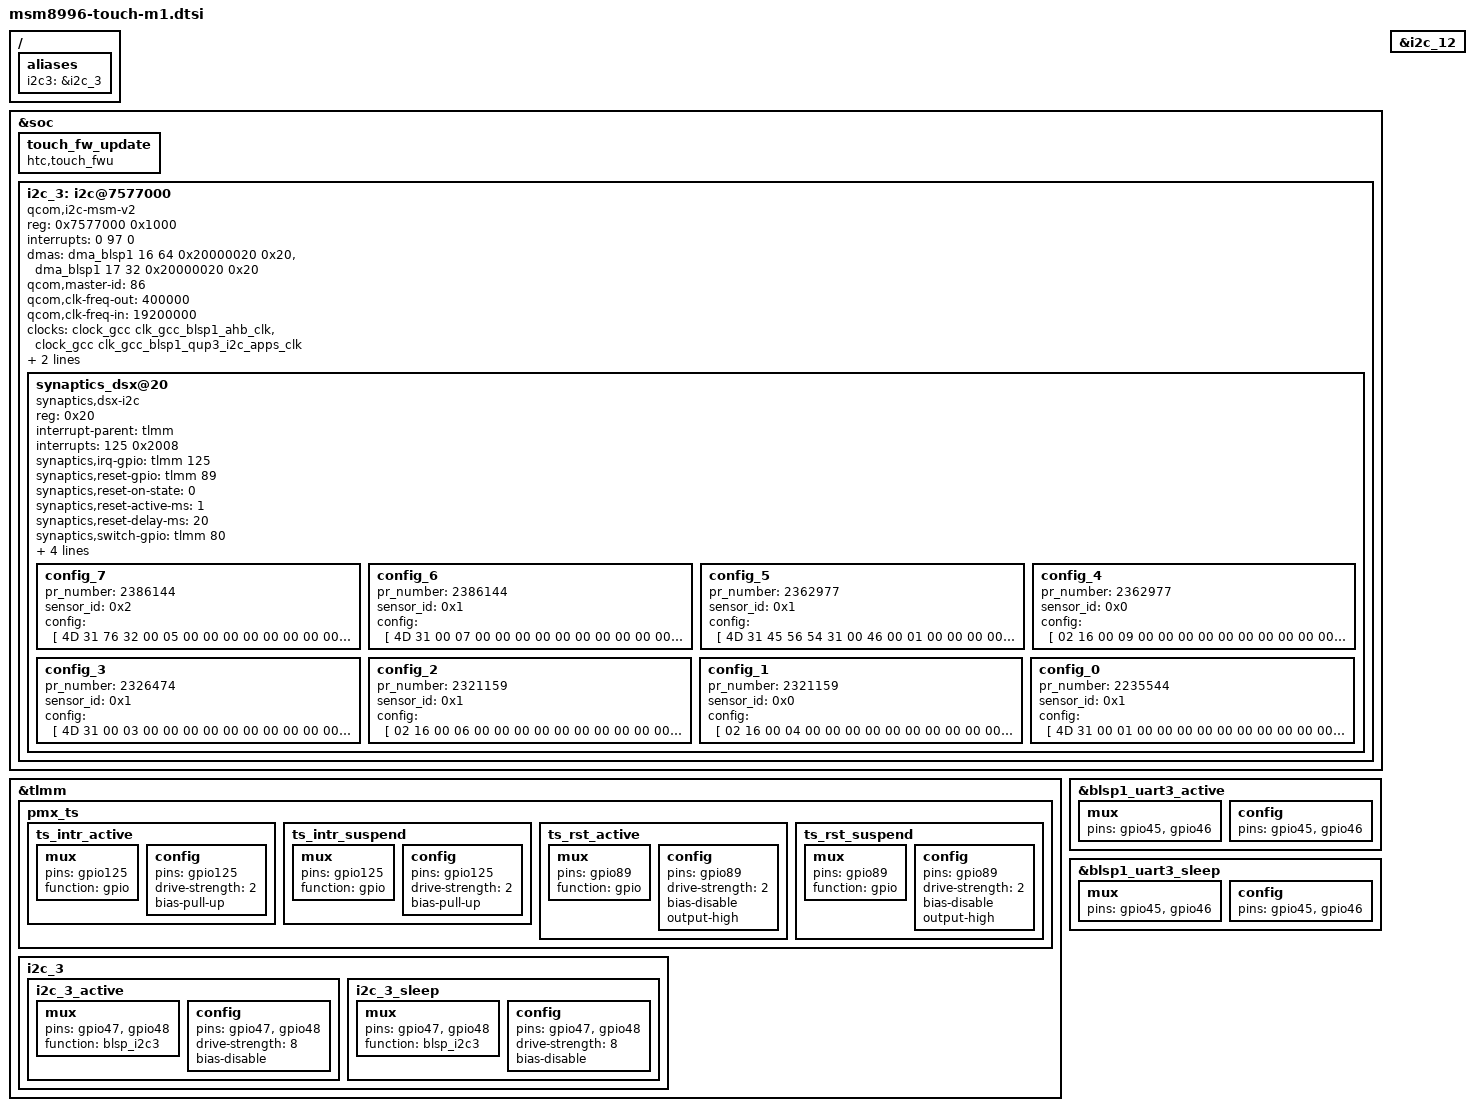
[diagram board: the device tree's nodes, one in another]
&soc {
	touch_fw_update {
		compatible = "htc,touch_fwu";
	};
};

&tlmm {
	pmx_ts {
		ts_intr_active:ts_intr_active {
			mux {
				pins = "gpio125";
				function = "gpio";
			};

			config {
				pins = "gpio125";
				drive-strength = <2>;
				bias-pull-up;
			};
		};
		ts_intr_suspend:ts_intr_suspend {
			mux {
				pins = "gpio125";
				function = "gpio";
			};

			config {
				pins = "gpio125";
				drive-strength = <2>;
				bias-pull-up;
			};
		};

		ts_rst_active:ts_rst_active {
			mux {
				pins = "gpio89";
				function = "gpio";
			};

			config {
				pins = "gpio89";
				drive-strength = <2>;
				bias-disable; /* No PULL */
				output-high;
			};
		};
		ts_rst_suspend:ts_rst_suspend {
			mux {
				pins = "gpio89";
				function = "gpio";
			};

			config {
				pins = "gpio89";
				drive-strength = <2>;
				bias-disable;
				output-high;
			};
		};
	};

	i2c_3 {
		i2c_3_active: i2c_3_active {
			mux {
				pins = "gpio47", "gpio48";
				function = "blsp_i2c3";
			};

			config {
				pins = "gpio47", "gpio48";
				drive-strength = <8>;
				bias-disable;
			};
		};

		i2c_3_sleep: i2c_3_sleep {
			mux {
				pins = "gpio47", "gpio48";
				function = "blsp_i2c3";
			};

			config {
				pins = "gpio47", "gpio48";
				drive-strength = <8>;
				bias-disable;
			};
		};
	};
};

&blsp1_uart3_active {
	mux {
		pins = "gpio45", "gpio46";
	};

	config {
		pins = "gpio45", "gpio46";
	};
};

&blsp1_uart3_sleep {
	mux {
		pins = "gpio45", "gpio46";
	};

	config {
		pins = "gpio45", "gpio46";
	};
};

/ {
	aliases {
		i2c3 = &i2c_3;
	};
};

&soc {
	i2c_3: i2c@7577000 { /* BLSP1 QUP3 */
		compatible = "qcom,i2c-msm-v2";
		#address-cells = <1>;
		#size-cells = <0>;
		reg = <0x7577000  0x1000>;
		reg-names = "qup_phys_addr";
		interrupt-names = "qup_irq";
		interrupts = <0 97 0>;
		dmas = <&dma_blsp1 16 64 0x20000020 0x20>,
			<&dma_blsp1 17 32 0x20000020 0x20>;
		dma-names = "tx", "rx";
		qcom,master-id = <86>;
		qcom,clk-freq-out = <400000>;
		qcom,clk-freq-in  = <19200000>;
		clock-names = "iface_clk", "core_clk";
		clocks = <&clock_gcc clk_gcc_blsp1_ahb_clk>,
			 <&clock_gcc clk_gcc_blsp1_qup3_i2c_apps_clk>;
		pinctrl-names = "i2c_active", "i2c_sleep";
		pinctrl-0 = <&i2c_3_active>;
		pinctrl-1 = <&i2c_3_sleep>;
	};
};

&i2c_12 {
	/delete-node/ synaptics@20;
};

&i2c_3 {
	synaptics_dsx@20 {
		compatible = "synaptics,dsx-i2c";
		reg = <0x20>;
		interrupt-parent = <&tlmm>;
		interrupts = <125 0x2008>;
		synaptics,irq-gpio = <&tlmm 125 0x2008>;  /* IRQF_ONESHOT | IRQF_TRIGGER_LOW */
		synaptics,reset-gpio = <&tlmm 89 0x00>;
		synaptics,reset-on-state = <0>;
		synaptics,reset-active-ms = <1>;
		synaptics,reset-delay-ms = <20>;
		synaptics,switch-gpio = <&tlmm 80 0x00>;
		synaptics,update-feature = <3>;
		synaptics,tw-pin-mask = <0x3>;
		pinctrl-names = "pmx_ts_active", "pmx_ts_suspend";
		pinctrl-0 = <&ts_rst_active &ts_intr_active>;
		pinctrl-1 = <&ts_rst_suspend &ts_intr_suspend>;

		config_7 { /* S3708, EVT2 w/o Force */
			pr_number     = <2386144>;
			sensor_id = <0x2>;
			config = [
				4D 31 76 32 00 05 00 00
				00 00 00 00 00 00 00 00
				00 00 00 00 00 00 00 00
				00 00 00 00 00 00 00 00
				00 07 01 14 05 51 0E 9F
				05 FF 09 39 40 9E 40 00
				00 20 20 11 1E 1E 05 F1
				10 9F 02 2D 1C 00 1B 00
				DC CC 55 CC 25 0D 05 8C
				00 00 10 12 78 0F 0A 78
				00 01 01 07 04 04 32 28
				08 7D 26 26 80 80 00 00
				C8 01 64 00 05 0A 00 FF
				05 01 28 FF C0 53 5B 80
				4A 26 00 40 50 32 50 00
				00 00 00 9F 05 FF 09 3C
				32 00 00 00 00 9F 05 FF
				09 1E 05 1E 04 0A 04 0A
				00 0A 04 04 00 0A 78 02
				00 7D 00 02 00 C8 00 00
				00 96 00 00 00 00 01 05
				0A 00 00 00 78 00 96 00
				32 00 00 00 00 00 00 00
				00 00 0D 00 00 14 03 0C
				0F 0A 00 4B 00 00 FF FF
				FF FF FF FF FF FF FF FF
				FF FF FF FF FF FF FF FF
				FF FF FF FF FF FF FF FF
				FF FF FF FF FF FF FF 00
				01 00 00 32 00 14 00 14
				00 64 00 64 00 10 00 10
				00 7D 00 7D 00 40 66 58
				1B 28 00 FF FF FF FF FF
				FF FF FF FF FF FF FF FF
				FF FF FF 01 00 00 00 00
				00 00 00 00 00 00 00 00
				00 00 00 00 00 00 00 00
				00 00 FF 00 FF 14 55 09
				0E 3C 0A 0F 64 64 00 00
				00 00 00 00 00 00 00 00
				00 00 00 00 00 00 00 00
				FF FF FF FF FF FF FF FF
				FF FF FF FF FF FF FF FF
				FF FF FF FF FF FF FF FF
				FF FF FF FF FF FF FF FF
				FF FF FF FF FF FF FF FF
				FF FF FF FF FF FF FF FF
				FF FF FF FF FF FF FF FF
				FF FF FF FF FF FF FF FF
				00 00 A0 00 80 04 1B 00
				00 FF E8 03 FF FF CC 03
				98 3A 00 C0 80 04 10 0A
				18 00 79 08 05 00 01 2C
				01 03 00 03 03 07 07 03
				2C 01 01 04 03 2F 00 15
				00 00 00 05 00 02 27 83
				2E 00 15 00 01 00 05 00
				02 28 83 2D 00 14 00 02
				00 05 00 02 29 03 2C 00
				14 00 03 00 05 00 02 29
				83 2B 00 13 00 05 00 03
				00 01 24 03 29 00 13 00
				07 00 03 00 01 25 83 28
				00 12 00 09 00 03 00 01
				27 82 26 00 11 00 0B 00
				03 00 01 28 03 03 03 03
				03 03 03 03 03 03 03 03
				03 03 03 03 03 00 00 00
				00 00 00 00 00 00 00 00
				00 00 00 00 00 00 23 00
				06 00 50 00 0A 32 00 01
				1B 01 06 46 00 28 00 28
				00 64 00 1E 03 0C 0C 14
				28 04 00 00 00 00 00 00
				00 00 00 00 14 00 80 07
				01 07 07 1D 1D 00 00 07
				07 01 07 07 1D 1D 00 00
				07 04 04 50 00 07 03 00
				2F 22 00 05 0B 00 22 02
				00 00 00 0D BB BB AA 0D
				66 66 00 0D 00 00 AA 0D
				EE EE 00 01 00 DA 00 13
				00 04 00 71 76 74 7A 7C
				7D 7A 7B 7D 7D 80 7F 7D
				7C 76 7A 76 80 80 80 80
				80 80 80 80 80 80 80 80
				80 80 80 80 80 78 7C 80
				7C 7A 7D 7B 7F 7C 7A 7A
				7B 7A 78 76 73 71 71 6E
				69 69 68 69 66 5D 5D 5F
				57 53 4E 80 80 80 80 00
				00 00 FF FF FF FF FF FF
				FF FF 51 51 51 51 CD 0D
				04 83 10 10 10 10 61 24
				64 01 17 16 12 11 0F 10
				0B 0A 05 04 18 1A 0D 13
				0E 08 09 FF FF FF FF FF
				FF FF FF FF FF FF FF FF
				FF FF FF FF 30 2E 2F 28
				29 2A 2C 2B 26 25 23 24
				22 35 39 36 37 33 32 2D
				27 34 38 31 3A 3B 3E 3D
				3C 3F FF FF FF FF 00 10
				00 10 00 10 00 10 80 80
				80 80 80 80 80 80 80 80
				80 80 80 80 80 80 80 80
				80 80 80 80 80 80 80 80
				80 80 80 80 80 80 80 80
				C0 B3 A6 9A 8D 80 80 80
				80 80 80 80 80 80 80 80
				80 80 80 80 80 80 80 80
				80 80 80 80 80 80 80 80
				80 80 00 18 00 18 00 10
				00 10 00 00 1C 1D 1E 1F
				FF FF FF FF 00 00 0F 00
				44 44 A0
			];
		};

		config_6 { /* S3708, EVT1 w/o Force */
			pr_number     = <2386144>;
			sensor_id = <0x1>;
			config = [
				4D 31 00 07 00 00 00 00
				00 00 00 00 00 00 00 00
				00 00 00 00 00 00 00 00
				00 00 00 00 00 00 00 00
				00 0F 01 14 05 51 0E 9F
				05 FF 09 39 40 9E 40 00
				00 20 00 11 1E 1E 05 CA
				10 19 02 2D 19 01 18 01
				80 D2 DF D0 25 0D 05 8C
				00 00 0E 10 50 0F 0A 78
				00 01 01 07 04 04 32 28
				08 7D 26 26 80 80 00 00
				C8 01 64 00 05 28 00 FF
				05 01 28 FF C0 53 5B 80
				5A 1A 00 40 50 3C 50 00
				00 00 00 4C 04 6C 07 3C
				32 00 00 00 00 4C 04 6C
				07 1E 05 1E 04 0A 04 0A
				00 0A 04 04 00 0A 78 02
				00 7D 00 02 00 C8 00 00
				00 96 00 00 00 00 01 05
				0A 00 00 00 78 00 96 00
				32 00 00 00 00 00 00 00
				00 00 0D 00 00 14 03 0C
				0F 0A 00 4B 00 00 FF FF
				FF FF FF FF FF FF FF FF
				FF FF FF FF FF FF FF FF
				FF FF FF FF FF FF FF FF
				FF FF FF FF FF FF FF 00
				01 00 00 32 00 14 00 14
				00 64 00 64 00 10 00 10
				00 7D 00 7D 00 40 66 58
				1B 28 00 FF FF FF FF FF
				FF FF FF FF FF FF FF FF
				FF FF FF 01 00 00 00 00
				00 00 00 00 00 00 00 00
				00 00 00 00 00 00 00 00
				00 00 FF 00 FF 14 55 09
				0E 3C 0A 0F 64 64 00 00
				00 00 00 00 00 00 00 00
				00 00 00 00 00 00 00 00
				FF FF FF FF FF FF FF FF
				FF FF FF FF FF FF FF FF
				FF FF FF FF FF FF FF FF
				FF FF FF FF FF FF FF FF
				FF FF FF FF FF FF FF FF
				FF FF FF FF FF FF FF FF
				FF FF FF FF FF FF FF FF
				FF FF FF FF FF FF FF FF
				00 00 64 00 80 04 1B 00
				00 FF 40 1F FF FF CC 03
				98 3A 00 C0 80 04 10 0A
				18 00 79 08 08 00 01 10
				27 06 00 02 02 07 07 05
				10 27 01 04 03 2F 00 15
				00 00 00 05 00 02 27 83
				2E 00 15 00 01 00 05 00
				02 28 83 2D 00 14 00 02
				00 05 00 02 29 03 2C 00
				14 00 03 00 05 00 02 29
				83 2B 00 13 00 05 00 03
				00 01 24 03 29 00 13 00
				07 00 03 00 01 25 83 28
				00 12 00 09 00 03 00 01
				27 82 26 00 11 00 0B 00
				03 00 01 28 03 03 03 03
				03 03 03 03 03 03 03 03
				03 03 03 03 03 00 00 00
				00 00 00 00 00 00 00 00
				00 00 00 00 00 00 23 00
				06 00 50 00 0A 19 00 01
				1B 01 06 46 00 28 00 28
				00 64 00 1E 03 0C 0C 14
				28 04 00 00 00 00 00 00
				00 00 00 00 14 00 80 07
				01 07 07 1D 1D 00 00 07
				07 01 07 07 1D 1D 00 00
				07 04 04 50 00 07 03 00
				2F 22 00 05 0B 00 22 02
				00 00 00 0D BB BB AA 0D
				66 66 00 0D 00 00 00 0D
				EE EE AA 01 00 DA 00 13
				00 04 00 71 76 74 7A 7C
				7D 7A 7B 7D 7D 80 7F 7D
				7C 76 7A 76 80 80 80 80
				80 80 80 80 80 80 80 80
				80 80 80 80 80 78 7C 80
				7C 7A 7D 7B 7F 7C 7A 7A
				7B 7A 78 76 73 71 71 6E
				69 69 68 69 66 5D 5D 5F
				57 53 4E 80 80 80 80 00
				00 00 FF FF FF FF FF FF
				FF FF 51 51 51 51 CD 0D
				04 83 10 10 10 10 61 24
				64 01 36 12 35 13 39 1A
				38 31 32 3A 37 14 34 15
				33 17 11 FF FF FF FF FF
				FF FF FF FF FF FF FF FF
				FF FF FF FF 2E 2D 30 28
				2F 2A 29 2C 27 2B 1B 1D
				1E 1F 1C 0D 10 0F 0C 07
				0E 08 09 03 06 02 0A 0B
				04 05 FF FF FF FF 00 10
				00 10 00 10 00 10 80 80
				80 80 80 80 80 80 80 80
				80 80 80 80 80 80 80 80
				80 80 80 80 80 80 80 80
				80 80 80 80 80 80 80 80
				C0 B3 A6 9A 8D 80 80 80
				80 80 80 80 80 80 80 80
				80 80 80 80 80 80 80 80
				80 80 80 80 80 80 80 80
				80 80 00 18 00 18 00 10
				00 10 00 00 16 19 18 24
				FF FF FF FF 0B 0B 04 00
				44 44 FA
			];
		};

		config_5 { /* S3718, EVT1 w/ Force */
			pr_number     = <2362977>;
			sensor_id = <0x1>;
			config = [
				4D 31 45 56 54 31 00 46
				00 01 00 00 00 00 00 00
				00 00 00 00 00 00 00 00
				00 00 00 00 00 00 00 00
				00 47 03 1E 05 51 0E A0
				05 00 0A 39 40 9E 40 00
				00 00 00 11 1E 01 1E 05
				DB 13 D6 04 2D 1B 02 1B
				02 1B D7 02 D5 25 0D 05
				8C 00 02 40 0C 13 80 0F
				0A 20 1A 01 01 26 26 80
				80 00 00 03 80 03 0C 06
				00 20 0F 01 28 00 C0 53
				5B 80 5C 25 01 40 40 32
				00 00 00 00 00 00 00 00
				00 00 00 CD 0A 00 09 00
				00 FF FF FF FF FF FF FF
				FF FF FF FF FF FF FF FF
				FF FF FF FF FF FF FF FF
				FF FF FF FF FF FF FF FF
				FF FF 00 01 00 00 8C 00
				00 00 00 00 2C 01 2C 01
				10 00 10 00 C8 00 C8 00
				66 66 88 13 00 00 FF FF
				FF FF FF FF FF FF FF FF
				FF FF FF FF FF FF 00 6C
				00 CC 03 C0 00 C0 06 36
				00 02 04 60 00 20 07 09
				09 00 00 00 00 FF 00 FF
				FF 55 09 0E 3C 0A 0A 64
				64 FF FF FF FF FF FF FF
				FF FF FF FF FF FF FF FF
				FF FF FF FF FF FF FF FF
				FF FF FF FF FF FF FF FF
				FF FF FF FF FF FF FF FF
				FF FF FF FF FF FF FF FF
				FF FF FF FF FF FF FF FF
				FF FF FF FF FF FF FF FF
				FF 17 05 05 00 0F 00 BC
				02 1E 00 05 00 0F 00 BC
				02 1E 00 0A 19 01 0C 00
				02 01 0C 00 02 AF 01 01
				01 01 01 00 00 00 00 00
				32 00 0A 00 96 00 0A 00
				09 00 FF FF FF FF FF FF
				FF FF FF FF FF FF FF FF
				FF 21 3B 00 26 01 20 3F
				3C 25 3D 22 23 3E FF FF
				07 01 07 07 1D 1D 00 00
				07 00 07 01 07 07 1D 1D
				00 00 07 00 04 04 50 00
				07 03 00 35 22 00 05 0B
				00 22 02 00 0D 88 88 00
				0D BB BB 8A 4C 1D A0 0E
				A0 00 00 73 00 80 04 1B
				00 00 FF 7C 8C FF FF FF
				FF FF FF 00 C0 80 04 10
				0A 18 00 79 0C FF FF 01
				FF FF FF FF 00 FF FF FF
				FF 02 02 07 07 05 46 A5
				01 04 03 2F 00 15 00 00
				00 05 00 02 27 03 2D 00
				14 00 02 00 05 00 02 29
				83 2B 00 14 00 04 00 05
				00 02 2A 83 2A 00 13 00
				06 00 03 00 01 25 03 28
				00 12 00 09 00 03 00 01
				27 02 26 00 11 00 0C 00
				03 00 01 28 82 24 00 10
				00 0F 00 07 00 02 25 82
				22 00 10 00 12 00 07 00
				02 26 03 03 03 03 03 03
				03 03 03 03 03 03 03 03
				03 03 03 00 00 00 00 00
				00 00 00 00 00 00 00 00
				00 00 00 00 23 00 06 00
				A6 00 14 64 02 01 1B 00
				00 08 08 A0 00 A0 00 50
				50 00 00 00 00 00 00 00
				00 14 80 07 01 07 07 1D
				1D 00 00 07 07 01 07 07
				1D 1D 00 00 07 04 04 50
				00 07 03 00 2F 22 00 05
				0B 00 22 02 00 00 00 0D
				FF FF 55 0D 44 44 00 13
				13 13 13 12 13 13 13 13
				13 13 13 14 14 14 14 17
				04 07 06 05 05 03 05 06
				06 06 04 05 05 00 00 00
				00 18 17 16 16 16 16 16
				15 15 15 15 15 15 15 15
				15 15 15 15 15 15 15 15
				15 15 15 14 14 14 15 00
				00 00 00 01 00 F8 00 45
				00 05 00 76 78 7A 7B 7A
				7D 7D 7F 7D 7F 7D 80 7C
				7D 7B 7A 78 00 00 00 00
				00 00 00 00 00 00 00 00
				00 00 00 00 00 7A 78 7A
				7D 7D 80 7A 77 7A 72 77
				6F 73 72 6E 6C 6A 64 64
				61 57 54 54 51 4A 3F 38
				3A 34 31 00 00 00 00 00
				04 03 05 00 00 00 FF FF
				FF FF FF FF FF FF 51 51
				51 51 CD 0D 04 01 36 12
				35 13 39 1A 38 31 32 3A
				37 14 34 15 33 17 11 FF
				FF FF FF FF FF FF FF FF
				FF FF FF FF FF FF FF FF
				2E 2D 30 28 2F 2A 29 2C
				27 2B 1B 1D 1E 1F 1C 0D
				10 0F 0C 07 0E 08 09 03
				06 02 0A 0B 04 05 FF FF
				FF FF 00 00 16 19 18 24
				FF FF FF FF 0B 0B 04 A1
				00 50 00 00 00 C8 50 05
				09 A0 0E A0 00 00 00 3C
				5C 00 00 00 08 7F 00 04
				02 04 3C 00 00 00 00 00
				00 00 A0 05 00 0A 99 00
			];
		};

		config_4 { /* S3718, prototype P */
			pr_number     = <2362977>;
			sensor_id = <0x0>;
			config = [
				02 16 00 09 00 00 00 00
				00 00 00 00 00 00 00 00
				00 00 00 00 00 00 00 00
				00 00 00 00 00 00 00 00
				00 07 03 1E 05 51 0E A0
				05 00 0A 39 40 9E 40 00
				00 39 00 11 1E 01 1E 05
				DB 13 D6 04 2D 30 00 30
				00 8F D9 E4 D8 25 0D 05
				8C 00 C2 40 0A 0C 80 0F
				0A 50 1A 01 01 26 26 80
				80 00 00 03 80 03 0C 06
				00 20 0F 01 28 00 C0 53
				5B 80 33 0D 00 40 40 32
				00 00 00 00 00 00 00 00
				00 00 00 EF 0A 00 09 00
				00 FF FF FF FF FF FF FF
				FF FF FF FF FF FF FF FF
				FF FF FF FF FF FF FF FF
				FF FF FF FF FF FF FF FF
				FF FF 00 01 00 00 8C 00
				00 00 00 00 2C 01 2C 01
				10 00 10 00 C8 00 C8 00
				66 66 88 13 00 00 FF FF
				FF FF FF FF FF FF FF FF
				FF FF FF FF FF FF 00 6C
				00 CC 03 C0 00 C0 06 36
				00 02 04 60 00 20 07 09
				09 00 00 00 00 FF 00 FF
				FF 55 09 0E 3C 0A 0A 64
				64 FF FF FF FF FF FF FF
				FF FF FF FF FF FF FF FF
				FF FF FF FF FF FF FF FF
				FF FF FF FF FF FF FF FF
				FF FF FF FF FF FF FF FF
				FF FF FF FF FF FF FF FF
				FF FF FF FF FF FF FF FF
				FF FF FF FF FF FF FF FF
				FF 17 05 05 00 0F 00 BC
				02 1E 00 05 00 0F 00 BC
				02 1E 00 0A 19 01 0C 00
				02 01 0C 00 02 AF 01 01
				01 01 01 00 00 00 00 00
				32 00 0A 00 96 00 0A 00
				09 00 FF FF FF FF FF FF
				FF FF FF FF FF FF FF FF
				FF FF FF FF FF FF FF FF
				FF FF FF FF FF FF FF FF
				07 01 07 07 1D 1D 00 00
				07 00 07 01 07 07 1D 1D
				00 00 07 00 04 04 50 00
				07 03 00 35 22 00 05 0B
				00 22 02 00 0D 88 88 00
				0D BB BB 8A 4C 1D A0 0E
				A0 00 00 77 00 80 04 1B
				00 00 FF 47 26 FF FF FF
				FF FF FF 00 C0 80 04 10
				0A 18 00 79 0C FF FF 01
				FF FF FF FF 00 FF FF FF
				FF 02 02 07 07 05 08 2D
				01 04 03 2A 00 13 00 00
				00 03 00 01 25 83 28 00
				12 00 02 00 03 00 01 27
				83 27 00 11 00 04 00 03
				00 01 28 82 26 00 11 00
				06 00 03 00 01 29 02 24
				00 10 00 08 00 07 00 02
				25 82 23 00 10 00 0A 00
				07 00 02 26 82 22 00 0F
				00 0C 00 07 00 02 27 02
				21 00 0F 00 0E 00 04 00
				01 23 03 03 03 03 03 03
				03 03 03 03 03 03 03 03
				03 04 03 00 00 00 00 00
				00 00 00 00 00 00 00 00
				00 00 00 00 2A 00 06 00
				A6 00 14 64 02 01 1B 00
				00 08 08 A0 00 A0 00 50
				50 00 00 00 00 00 00 00
				00 12 80 07 01 07 07 1D
				1D 00 00 07 07 01 07 07
				1D 1D 00 00 07 04 04 50
				00 07 03 00 2A 22 00 05
				0B 00 22 02 00 00 00 0D
				EE EE FF 0D AA AA 55 14
				13 14 13 14 13 13 13 13
				13 13 13 13 13 14 15 17
				00 00 00 00 00 00 00 00
				00 00 00 00 00 00 00 00
				00 1C 16 16 15 16 15 15
				15 16 15 15 15 15 15 15
				14 14 15 15 15 15 14 14
				14 14 14 14 14 14 15 00
				00 00 00 01 00 06 01 74
				00 04 00 71 74 74 74 76
				7A 7C 7B 78 80 7D 7D 80
				80 7D 7D 77 00 00 00 00
				00 00 00 00 00 00 00 00
				00 00 00 00 00 7A 74 78
				74 7F 7A 74 78 7A 73 80
				78 7C 72 77 73 6E 74 6F
				6F 64 66 5C 5D 61 56 4F
				53 51 56 00 00 00 00 00
				04 03 05 FF F0 FF FF FF
				FF FF FF FF FF FF 05 02
				36 3A 35 1A 31 13 36 3A
				35 1A 31 13 38 15 32 14
				37 34 18 17 12 11 33 FF
				FF FF FF FF FF FF FF FF
				FF FF FF FF FF FF FF FF
				30 2F 29 2C 2E 28 2A 2B
				2D 27 1B 1D 1E 1F 1C 0F
				10 0C 07 06 0D 0E 08 09
				02 0A 0B 04 05 03 FF FF
				FF FF 18 24 16 19 24 39
				FF FF FF FF 0B 0B 04 C8
				50 05 09 A0 0E A0 00 00
				00 32 5C 00 00 00 08 7F
				00 04 02 04 3C 00 00 00
				00 00 00 00 A0 05 00 0A
				99 00 00 00 00 00 00 00
			];
		};

		config_3 { /* S3708, EVT1 w/o Force */
			pr_number     = <2326474>;
			sensor_id = <0x1>;
			config = [
				4D 31 00 03 00 00 00 00
				00 00 00 00 00 00 00 00
				00 00 00 00 00 00 00 00
				00 00 00 00 00 00 00 00
				00 07 03 1E 05 51 0E A0
				05 00 0A 39 40 9E 40 00
				00 20 00 11 1E 1E 05 CA
				10 19 02 2D 19 01 18 01
				05 E1 1F E1 25 0D 05 8C
				00 00 0E 10 6E 0F 0A 78
				00 01 01 07 04 04 32 28
				08 B4 26 26 80 80 00 00
				C8 01 64 00 05 0A 00 FF
				05 01 28 FF C0 53 5B 80
				45 12 00 40 50 3C 50 00
				00 00 00 4C 04 6C 07 3C
				32 00 00 00 00 4C 04 6C
				07 1E 05 1E 04 0A 04 0A
				00 0A 04 04 00 0A 78 02
				00 7D 00 02 00 C8 00 00
				00 96 00 00 00 00 01 05
				0A 00 00 00 78 00 96 00
				32 00 00 00 00 00 00 00
				00 00 0D 00 00 14 03 0C
				0F 0A 00 4B 00 00 FF FF
				FF FF FF FF FF FF FF FF
				FF FF FF FF FF FF FF FF
				FF FF FF FF FF FF FF FF
				FF FF FF FF FF FF FF 00
				01 00 00 32 00 14 00 14
				00 64 00 64 00 10 00 10
				00 7D 00 7D 00 40 66 58
				1B 28 00 FF FF FF FF FF
				FF FF FF FF FF FF FF FF
				FF FF FF 01 00 00 00 00
				00 00 00 00 00 00 00 00
				00 00 00 00 00 00 00 00
				00 00 FF 00 FF 14 55 09
				0E 3C 0A 0F 64 64 00 00
				00 00 00 00 00 00 00 00
				00 00 00 00 00 00 00 00
				FF FF FF FF FF FF FF FF
				FF FF FF FF FF FF FF FF
				FF FF FF FF FF FF FF FF
				FF FF FF FF FF FF FF FF
				FF FF FF FF FF FF FF FF
				FF FF FF FF FF FF FF FF
				FF FF FF FF FF FF FF FF
				FF FF FF FF FF FF FF FF
				00 00 64 00 80 04 1B 00
				00 FF 40 1F FF FF CC 03
				98 3A 00 C0 80 04 10 0A
				18 00 79 08 08 00 01 10
				27 06 00 02 02 07 07 05
				10 27 01 04 83 2F 00 15
				00 00 00 05 00 02 27 83
				2E 00 15 00 01 00 05 00
				02 28 83 2D 00 14 00 02
				00 05 00 02 29 83 2C 00
				14 00 03 00 05 00 02 29
				83 2B 00 13 00 05 00 03
				00 01 24 03 29 00 13 00
				07 00 03 00 01 25 83 28
				00 12 00 09 00 03 00 01
				27 82 26 00 11 00 0B 00
				03 00 01 28 03 03 03 03
				03 03 03 03 03 03 03 03
				03 03 03 03 03 00 00 00
				00 00 00 00 00 00 00 00
				00 00 00 00 00 00 23 00
				06 00 A6 00 14 32 00 01
				1B 01 06 46 46 50 00 50
				00 50 50 1E 03 0C 0C 14
				28 04 00 00 00 00 00 00
				00 00 00 00 14 00 80 07
				01 07 07 1D 1D 00 00 07
				07 01 07 07 1D 1D 00 00
				07 04 04 50 00 07 03 00
				2F 22 00 05 0B 00 22 02
				00 00 00 0D BB BB AA 0D
				66 66 00 01 64 0D 00 00
				00 0D EE EE AA 00 00 00
				FF FF FF FF FF FF FF FF
				51 51 51 51 CD 0D 04 83
				10 10 10 10 61 24 64 01
				36 12 35 13 39 1A 38 31
				32 3A 37 14 34 15 33 17
				11 FF FF FF FF FF FF FF
				FF FF FF FF FF FF FF FF
				FF FF 2E 2D 30 28 2F 2A
				29 2C 27 2B 1B 1D 1E 1F
				1C 0D 10 0F 0C 07 0E 08
				09 03 06 02 0A 0B 04 05
				FF FF FF FF 00 10 00 10
				00 10 00 10 80 80 80 80
				80 80 80 80 80 80 80 80
				80 80 80 80 80 80 80 80
				80 80 80 80 80 80 80 80
				80 80 80 80 80 80 80 80
				80 80 80 80 80 80 80 80
				80 80 80 80 80 80 80 80
				80 80 80 80 80 80 80 80
				80 80 80 80 80 80 80 80
				00 10 00 10 00 10 00 10
				00 00 16 19 18 24 FF FF
				FF FF 0B 0B 04 00 44 44
				78
			];
		};

		config_2 { /* S3718, prototype M & EVT1 w/ Force */
			pr_number     = <2321159>;
			sensor_id = <0x1>;
			config = [
				02 16 00 06 00 00 00 00
				00 00 00 00 00 00 00 00
				00 00 00 00 00 00 00 00
				00 00 00 00 00 00 00 00
				04 4F 03 1E 05 51 0E 9F
				05 FF 09 39 40 9E 40 03
				03 03 03 11 1E 01 1E 05
				F5 28 1E 05 28 30 00 30
				00 87 E7 46 E7 25 0D 05
				8C 00 40 23 28 80 0F 0A
				20 1A 01 01 26 26 80 80
				00 00 03 C8 00 0D 14 00
				FF 0F 01 28 C0 C0 53 5B
				80 66 61 00 40 40 32 50
				00 00 00 00 00 00 00 4C
				04 6C 07 3C 32 00 00 00
				00 4C 04 6C 07 1E 05 1E
				04 0A 04 0A 00 0A 04 04
				00 00 00 00 00 00 00 00
				C5 0A 00 01 00 00 00 14
				03 0C 0F 0A 00 4B 00 00
				FF FF FF FF FF FF FF FF
				FF FF FF FF FF FF FF FF
				FF FF FF FF FF FF FF FF
				FF FF FF FF FF FF FF FF
				FF 00 00 00 00 FF 00 FF
				FF 55 09 0E 3C 0A 0A 64
				64 FF FF FF FF FF FF FF
				FF FF FF FF FF FF FF FF
				FF FF FF FF FF FF FF FF
				FF FF FF FF FF FF FF FF
				FF FF FF FF FF FF FF FF
				FF FF FF FF FF FF FF FF
				FF FF FF FF FF FF FF FF
				FF FF FF FF FF FF FF FF
				FF 17 05 05 00 0F 00 BC
				02 1E 00 05 00 0F 00 BC
				02 1E 00 0A 19 01 0C 00
				02 01 0C 00 02 AF 01 01
				01 01 01 00 00 00 00 00
				32 00 0A 00 96 00 0A 00
				09 00 00 00 00 00 00 00
				00 00 00 05 02 07 07 1F
				1F 06 06 07 00 07 01 07
				07 1D 1D 00 00 07 00 04
				04 50 00 07 03 00 35 22
				00 05 00 00 00 00 00 0D
				AA AA 55 0D BB BB 8A 4C
				1D A0 0E A0 00 01 82 00
				80 04 1B 00 00 FF FF FF
				FF FF FF FF FF FF 00 C0
				80 04 10 0A 18 00 79 0C
				FF FF 01 FF FF FF FF 00
				FF FF FF FF 04 04 07 07
				02 FF FF 01 04 04 36 00
				14 00 00 00 05 00 02 28
				84 35 00 14 00 01 00 05
				00 02 29 83 33 00 13 00
				03 00 03 00 01 24 83 31
				00 13 00 05 00 03 00 01
				25 83 2F 00 12 00 07 00
				03 00 01 27 83 2E 00 11
				00 09 00 03 00 01 28 83
				2C 00 11 00 0B 00 03 00
				01 29 83 2B 00 10 00 0D
				00 07 00 02 25 03 03 03
				03 03 03 03 03 03 03 03
				03 03 03 03 03 03 00 00
				00 00 00 00 00 00 00 00
				00 00 00 00 00 00 00 25
				00 06 00 A6 00 14 64 00
				01 1B 00 00 08 08 A0 00
				A0 00 50 50 00 00 00 00
				00 00 00 00 13 80 05 02
				07 07 1F 1F 06 06 07 05
				02 07 07 1F 1F 06 06 07
				04 04 50 00 07 04 00 36
				2D 00 05 0B 00 22 02 00
				00 00 96 96 96 96 96 96
				96 96 96 96 96 96 96 96
				96 96 96 FF FF FF FF FF
				FF FF FF FF FF FF FF FF
				FF FF FF FF 01 0D 99 99
				55 0D EE EE 00 00 00 00
				FF FF FF FF FF FF FF FF
				51 51 51 51 CD 0D 04 01
				36 12 35 13 39 1A 38 31
				32 3A 37 14 34 15 33 17
				11 FF FF FF FF FF FF FF
				FF FF FF FF FF FF FF FF
				FF FF 2E 2D 30 28 2F 2A
				29 2C 27 2B 1B 1D 1E 1F
				1C 0D 10 0F 0C 07 0E 08
				09 03 06 02 0A 0B 04 05
				FF FF FF FF 00 00 19 16
				25 18 FF FF FF FF 0B 0B
				04 FF FF FF FF FF FF FF
				FF FF FF FF FF FF FF FF
				FF FF FF FF FF FF FF FF
				FF FF FF FF FF FF FF FF
				FF FF FF 26 3E 3C 23 3F
				25 22 3D 21 3B 20 00 01
				FF FF FF FF FF FF FF FF
				FF FF FF FF FF FF FF FF
				FF FF FF FF FF B1 00 50
				00 00 00 C8 50 05 09 A0
				0E A0 00 00 00 32 5C 32
				96 0A 0A 00 00 01 40 40
				40 40 40 40 40 40 40 40
				40 40 40 00 00 00 00 00
				00 00 00 00 00 00 00 00
				00 00 00 00 00 00 00 00
				00 00 00 00 00 00 00 00
				00 00 00 00 00 00 00 00
				00 00 00 00 00 00 00 01
				01 01 01 01 01 01 01 01
				01 01 01 01 01 01 01 01
				01 01 01 01 01 01 01 01
				01 01 01 01 01 01 01 01
				01 01 01 01 01 01 01 01
				01 01 01 01 01 01 01 01
				01 01 01 01 01 01 01 01
				01 01 01 01 01 01 01 01
				01 01 01 01 01 01 01 01
				01 01 01 01 01 01 01 01
				01 01 01 01 01 00 00 00
				00 00
			];
		};

		config_1 { /* S3718, prototype P */
			pr_number     = <2321159>;
			sensor_id = <0x0>;
			config = [
				02 16 00 04 00 00 00 00
				00 00 00 00 00 00 00 00
				00 00 00 00 00 00 00 00
				00 00 00 00 00 00 00 00
				04 4F 03 1E 05 51 0E 9F
				05 FF 09 39 40 9E 40 03
				03 03 03 11 1E 01 1E 05
				F5 28 1E 05 28 30 00 30
				00 87 E7 46 E7 25 0D 05
				8C 00 40 23 28 80 0F 0A
				20 1A 01 01 26 26 80 80
				00 00 03 C8 00 0D 14 00
				FF 0F 01 28 C0 C0 53 5B
				80 66 61 00 40 40 32 50
				00 00 00 00 00 00 00 4C
				04 6C 07 3C 32 00 00 00
				00 4C 04 6C 07 1E 05 1E
				04 0A 04 0A 00 0A 04 04
				00 00 00 00 00 00 00 00
				C5 0A 00 01 00 00 00 14
				03 0C 0F 0A 00 4B 00 00
				FF FF FF FF FF FF FF FF
				FF FF FF FF FF FF FF FF
				FF FF FF FF FF FF FF FF
				FF FF FF FF FF FF FF FF
				FF 00 00 00 00 FF 00 FF
				FF 55 09 0E 3C 0A 0A 64
				64 FF FF FF FF FF FF FF
				FF FF FF FF FF FF FF FF
				FF FF FF FF FF FF FF FF
				FF FF FF FF FF FF FF FF
				FF FF FF FF FF FF FF FF
				FF FF FF FF FF FF FF FF
				FF FF FF FF FF FF FF FF
				FF FF FF FF FF FF FF FF
				FF 17 05 05 00 0F 00 BC
				02 1E 00 05 00 0F 00 BC
				02 1E 00 0A 19 01 0C 00
				02 01 0C 00 02 AF 01 01
				01 01 01 00 00 00 00 00
				32 00 0A 00 96 00 0A 00
				09 00 00 00 00 00 00 00
				00 00 00 05 02 07 07 1F
				1F 06 06 07 00 07 01 07
				07 1D 1D 00 00 07 00 04
				04 50 00 07 03 00 35 22
				00 05 00 00 00 00 00 0D
				AA AA 55 0D BB BB 8A 4C
				1D A0 0E A0 00 01 82 00
				80 04 1B 00 00 FF FF FF
				FF FF FF FF FF FF 00 C0
				80 04 10 0A 18 00 79 0C
				FF FF 01 FF FF FF FF 00
				FF FF FF FF 04 04 07 07
				02 FF FF 01 04 04 36 00
				14 00 00 00 05 00 02 28
				84 35 00 14 00 01 00 05
				00 02 29 83 33 00 13 00
				03 00 03 00 01 24 83 31
				00 13 00 05 00 03 00 01
				25 83 2F 00 12 00 07 00
				03 00 01 27 83 2E 00 11
				00 09 00 03 00 01 28 83
				2C 00 11 00 0B 00 03 00
				01 29 83 2B 00 10 00 0D
				00 07 00 02 25 03 03 03
				03 03 03 03 03 03 03 03
				03 03 03 03 03 03 00 00
				00 00 00 00 00 00 00 00
				00 00 00 00 00 00 00 25
				00 06 00 A6 00 14 64 00
				01 1B 00 00 08 08 A0 00
				A0 00 50 50 00 00 00 00
				00 00 00 00 13 80 05 02
				07 07 1F 1F 06 06 07 05
				02 07 07 1F 1F 06 06 07
				04 04 50 00 07 04 00 36
				2D 00 05 0B 00 22 02 00
				00 00 96 96 96 96 96 96
				96 96 96 96 96 96 96 96
				96 96 96 FF FF FF FF FF
				FF FF FF FF FF FF FF FF
				FF FF FF FF 01 0D 99 99
				55 0D EE EE 00 00 00 00
				FF FF FF FF FF FF FF FF
				51 51 51 51 CD 0D 04 01
				36 3A 35 1A 31 13 38 15
				32 14 37 34 18 17 12 11
				33 FF FF FF FF FF FF FF
				FF FF FF FF FF FF FF FF
				FF FF 30 2F 29 2C 2E 28
				2A 2B 2D 27 1B 1D 1E 1F
				1C 0F 10 0C 07 06 0D 0E
				08 09 02 0A 0B 04 05 03
				FF FF FF FF 00 00 16 19
				24 39 FF FF FF FF 0B 0B
				04 FF FF FF FF FF FF FF
				FF FF FF FF FF FF FF FF
				FF FF FF FF FF FF FF FF
				FF FF FF FF FF FF FF FF
				FF FF FF 26 3E 3C 23 3F
				25 22 3D 21 3B 20 00 01
				FF FF FF FF FF FF FF FF
				FF FF FF FF FF FF FF FF
				FF FF FF FF FF B1 00 50
				00 00 00 C8 50 05 09 A0
				0E A0 00 00 00 32 5C 32
				96 0A 0A 00 00 01 40 40
				40 40 40 40 40 40 40 40
				40 40 40 00 00 00 00 00
				00 00 00 00 00 00 00 00
				00 00 00 00 00 00 00 00
				00 00 00 00 00 00 00 00
				00 00 00 00 00 00 00 00
				00 00 00 00 00 00 00 01
				01 01 01 01 01 01 01 01
				01 01 01 01 01 01 01 01
				01 01 01 01 01 01 01 01
				01 01 01 01 01 01 01 01
				01 01 01 01 01 01 01 01
				01 01 01 01 01 01 01 01
				01 01 01 01 01 01 01 01
				01 01 01 01 01 01 01 01
				01 01 01 01 01 01 01 01
				01 01 01 01 01 01 01 01
				01 01 01 01 01 00 00 00
				00 00
			];
		};

		config_0 { /* S3708, EVT1 w/o Force */
			pr_number     = <2235544>;
			sensor_id = <0x1>;
			config = [
				4D 31 00 01 00 00 00 00
				00 00 00 00 00 00 00 00
				00 00 00 00 00 00 00 00
				00 00 00 00 00 00 00 00
				04 07 03 1E 05 51 0E 9F
				05 FF 09 39 40 9E 40 03
				03 03 03 11 1E 1E 05 F5
				28 1E 05 28 30 00 30 00
				F0 D2 F0 D2 25 0D 05 8C
				00 00 05 0F 80 0F 0A 20
				00 01 01 07 04 04 0A C0
				19 64 26 26 80 80 00 00
				C8 C0 53 5B 80 66 19 01
				40 40 32 50 00 00 00 00
				4C 04 6C 07 3C 32 00 00
				00 00 4C 04 6C 07 1E 05
				1E 04 0A 04 0A 00 0A 04
				04 00 0A 78 02 00 7D 00
				02 00 C8 00 00 00 96 00
				00 00 00 00 15 0A 00 00
				00 78 00 96 00 32 00 00
				00 00 00 00 00 00 00 0D
				00 00 14 03 0C 0F 0A 00
				4B 00 00 FF FF FF FF FF
				FF FF FF FF FF FF FF FF
				FF FF FF FF FF FF FF FF
				FF FF FF FF FF FF FF FF
				FF FF FF FF 00 01 00 00
				32 00 14 00 14 00 64 00
				64 00 10 00 10 00 7D 00
				7D 00 40 66 58 1B 28 00
				FF FF FF FF FF FF FF FF
				FF FF FF FF FF FF FF FF
				01 00 00 00 00 00 00 00
				00 00 00 00 00 00 00 00
				00 00 00 00 00 00 00 FF
				00 FF 14 55 09 0E 3C 0A
				0F 64 64 00 00 00 00 00
				00 00 00 00 00 00 00 00
				00 00 00 00 00 FF FF FF
				FF FF FF FF FF FF FF FF
				FF FF FF FF FF FF FF FF
				FF FF FF FF FF FF FF FF
				FF FF FF FF FF FF FF FF
				FF FF FF FF FF FF FF FF
				FF FF FF FF FF FF FF FF
				FF FF FF FF FF FF FF FF
				FF FF FF FF FF 00 00 82
				00 80 04 1B 00 00 FF FF
				FF FF FF FF FF FF FF 00
				C0 80 04 10 0A 18 00 79
				00 FF FF 01 FF FF FF FF
				04 04 07 07 02 FF FF 01
				04 03 2F 00 15 00 00 00
				05 00 02 27 83 2E 00 15
				00 01 00 05 00 02 28 83
				2D 00 14 00 02 00 05 00
				02 29 03 2C 00 14 00 03
				00 05 00 02 29 83 2B 00
				13 00 05 00 03 00 01 24
				03 29 00 13 00 07 00 03
				00 01 25 83 28 00 12 00
				09 00 03 00 01 27 82 26
				00 11 00 0B 00 03 00 01
				28 03 03 03 03 03 03 03
				03 03 03 03 03 03 03 03
				03 03 02 02 02 02 02 02
				02 02 02 02 02 02 02 02
				02 02 02 23 00 06 00 A6
				00 14 64 00 01 1B 01 00
				08 08 A0 00 A0 00 50 50
				1E 03 0C 0C 14 28 04 00
				00 00 00 00 00 00 00 00
				00 14 0A 80 07 07 07 06
				1B 1B 00 00 07 07 07 07
				06 1B 1B 00 00 07 04 04
				50 00 07 03 00 2F 22 00
				05 0B 00 22 02 00 00 00
				0D DD DD FF 0D EE EE 55
				01 46 0D EE EE 00 0D EE
				EE AA 00 00 00 FF FF FF
				FF FF FF FF FF 51 51 51
				51 CD 0D 04 83 10 10 10
				10 61 24 64 01 36 12 35
				13 39 1A 38 31 32 3A 37
				14 34 15 33 17 11 FF FF
				FF FF FF FF FF FF FF FF
				FF FF FF FF FF FF FF 2E
				2D 30 28 2F 2A 29 2C 27
				2B 1B 1D 1E 1F 1C 0D 10
				0F 0C 07 0E 08 09 03 06
				02 0A 0B 04 05 FF FF FF
				FF 00 10 00 10 00 10 00
				10 80 80 80 80 80 80 80
				80 80 80 80 80 80 80 80
				80 80 80 80 80 80 80 80
				80 80 80 80 80 80 80 80
				80 80 80 80 80 80 80 80
				80 80 80 80 80 80 80 80
				80 80 80 80 80 80 80 80
				80 80 80 80 80 80 80 80
				80 80 80 80 80 00 10 00
				10 00 10 00 10 00 00 16
				19 18 24 FF FF FF FF 0B
				0B 04 00 00 00
			];
		};
	};
};
